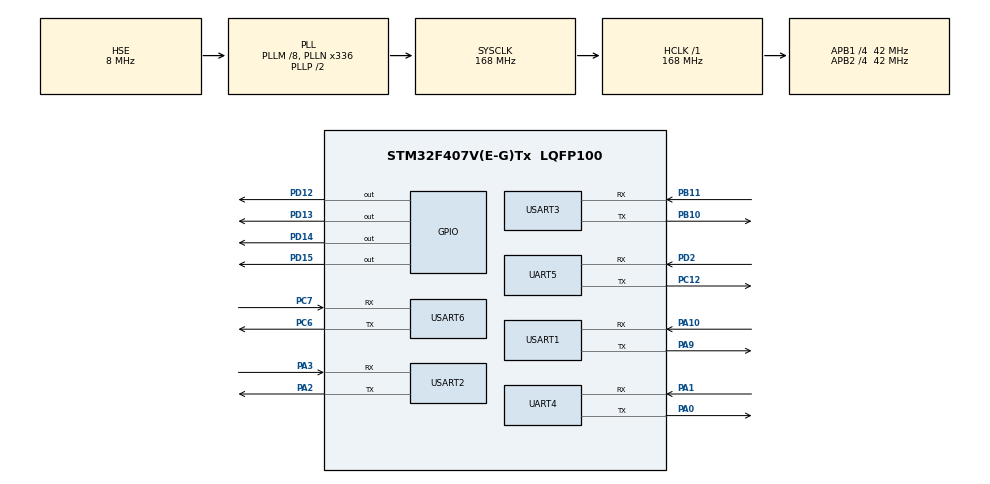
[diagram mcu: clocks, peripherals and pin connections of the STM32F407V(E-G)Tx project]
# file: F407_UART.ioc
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Mcu.Family=STM32F4
NVIC.USART3_IRQn=true\:0\:0\:false\:false\:true\:true\:true
Dma.USART2_RX.3.Mode=DMA_CIRCULAR
Dma.USART6_RX.5.FIFOMode=DMA_FIFOMODE_DISABLE
Dma.UART5_RX.1.MemInc=DMA_MINC_ENABLE
PH0-OSC_IN.Signal=RCC_OSC_IN
RCC.CortexFreq_Value=168000000
Dma.USART3_RX.4.Priority=DMA_PRIORITY_LOW
PB10.Mode=Asynchronous
Dma.USART6_RX.5.Priority=DMA_PRIORITY_LOW
NVIC.DMA1_Stream2_IRQn=true\:0\:0\:false\:false\:true\:false\:true
PC12.Signal=UART5_TX
Dma.USART1_RX.2.Instance=DMA2_Stream2
Dma.UART5_RX.1.Mode=DMA_CIRCULAR
Dma.USART3_RX.4.MemDataAlignment=DMA_MDATAALIGN_BYTE
Dma.USART6_RX.5.PeriphDataAlignment=DMA_PDATAALIGN_BYTE
PB11.Signal=USART3_RX
RCC.SYSCLKSource=RCC_SYSCLKSOURCE_PLLCLK
ProjectManager.StackSize=0x400
NVIC.UART5_IRQn=true\:0\:0\:false\:false\:true\:true\:true
Dma.USART6_RX.5.MemInc=DMA_MINC_ENABLE
PD13.Signal=GPIO_Output
Dma.USART6_RX.5.Instance=DMA2_Stream1
RCC.HCLKFreq_Value=168000000
RCC.APB2TimFreq_Value=84000000
PC7.Signal=USART6_RX
RCC.AHBFreq_Value=168000000
PH0-OSC_IN.Mode=HSE-External-Oscillator
RCC.HSE_VALUE=8000000
Dma.UART4_RX.0.MemDataAlignment=DMA_MDATAALIGN_BYTE
Dma.USART3_RX.4.PeriphInc=DMA_PINC_DISABLE
Dma.UART4_RX.0.PeriphDataAlignment=DMA_PDATAALIGN_BYTE
Dma.USART2_RX.3.Direction=DMA_PERIPH_TO_MEMORY
PH1-OSC_OUT.Mode=HSE-External-Oscillator
Mcu.Package=LQFP100
Dma.USART6_RX.5.PeriphInc=DMA_PINC_DISABLE
USART2.VirtualMode=VM_ASYNC
USART6.VirtualMode=VM_ASYNC
PD12.Signal=GPIO_Output
Dma.USART6_RX.5.Mode=DMA_CIRCULAR
PA10.Signal=USART1_RX
Dma.USART3_RX.4.Instance=DMA1_Stream1
RCC.APB2CLKDivider=RCC_HCLK_DIV4
Dma.USART2_RX.3.MemDataAlignment=DMA_MDATAALIGN_BYTE
NVIC.DMA2_Stream2_IRQn=true\:0\:0\:false\:false\:true\:false\:true
Dma.Request2=USART1_RX
Dma.Request1=UART5_RX
RCC.APB1TimFreq_Value=84000000
Dma.Request4=USART3_RX
Dma.Request3=USART2_RX
Dma.Request5=USART6_RX
NVIC.DMA1_Stream0_IRQn=true\:0\:0\:false\:false\:true\:false\:true
NVIC.USART1_IRQn=true\:0\:0\:false\:false\:true\:true\:true
Dma.Request0=UART4_RX
PD15.Signal=GPIO_Output
Dma.USART3_RX.4.FIFOMode=DMA_FIFOMODE_DISABLE
Dma.USART1_RX.2.MemDataAlignment=DMA_MDATAALIGN_BYTE
PA3.Signal=USART2_RX
NVIC.UART4_IRQn=true\:0\:0\:false\:false\:true\:true\:true
Dma.UART4_RX.0.MemInc=DMA_MINC_ENABLE
RCC.PLLSourceVirtual=RCC_PLLSOURCE_HSE
PA10.Mode=Asynchronous
Dma.USART2_RX.3.Instance=DMA1_Stream5
Dma.UART5_RX.1.MemDataAlignment=DMA_MDATAALIGN_BYTE
Dma.UART4_RX.0.Mode=DMA_CIRCULAR
PC6.Signal=USART6_TX
Dma.USART2_RX.3.PeriphDataAlignment=DMA_PDATAALIGN_BYTE
NVIC.DMA1_Stream1_IRQn=true\:0\:0\:false\:false\:true\:false\:true
NVIC.DMA2_Stream1_IRQn=true\:0\:0\:false\:false\:true\:false\:true
UART5.VirtualMode=Asynchronous
RCC.APB1CLKDivider=RCC_HCLK_DIV4
UART4.VirtualMode=Asynchronous
Dma.USART1_RX.2.PeriphInc=DMA_PINC_DISABLE
Dma.USART3_RX.4.PeriphDataAlignment=DMA_PDATAALIGN_BYTE
NVIC.USART2_IRQn=true\:0\:0\:false\:false\:true\:true\:true
PA0-WKUP.Signal=UART4_TX
NVIC.USART6_IRQn=true\:0\:0\:false\:false\:true\:true\:true
PA0-WKUP.Mode=Asynchronous
PA3.Mode=Asynchronous
Dma.UART5_RX.1.FIFOMode=DMA_FIFOMODE_DISABLE
Dma.USART2_RX.3.FIFOMode=DMA_FIFOMODE_DISABLE
PA9.Mode=Asynchronous
Dma.USART3_RX.4.Mode=DMA_CIRCULAR
Dma.UART4_RX.0.Direction=DMA_PERIPH_TO_MEMORY
PB11.Mode=Asynchronous
ProjectManager.TargetToolchain=STM32CubeIDE
NVIC.DMA1_Stream5_IRQn=true\:0\:0\:false\:false\:true\:false\:true
Dma.USART1_RX.2.Mode=DMA_CIRCULAR
PC6.Mode=Asynchronous
Dma.USART1_RX.2.PeriphDataAlignment=DMA_PDATAALIGN_BYTE
PA9.Signal=USART1_TX
Dma.UART4_RX.0.PeriphInc=DMA_PINC_DISABLE
RCC.LSE_VALUE=32768
PA1.Signal=UART4_RX
PB10.Signal=USART3_TX
PD2.Mode=Asynchronous
Dma.UART5_RX.1.Direction=DMA_PERIPH_TO_MEMORY
Dma.UART5_RX.1.Instance=DMA1_Stream0
PC12.Mode=Asynchronous
board=custom
Dma.USART1_RX.2.FIFOMode=DMA_FIFOMODE_DISABLE
RCC.VCOOutputFreq_Value=336000000
Dma.UART4_RX.0.FIFOMode=DMA_FIFOMODE_DISABLE
Dma.USART1_RX.2.Priority=DMA_PRIORITY_LOW
Dma.UART5_RX.1.PeriphInc=DMA_PINC_DISABLE
Dma.UART4_RX.0.Priority=DMA_PRIORITY_LOW
RCC.APB2Freq_Value=42000000
PA1.Mode=Asynchronous
Dma.USART1_RX.2.Direction=DMA_PERIPH_TO_MEMORY
Dma.USART6_RX.5.MemDataAlignment=DMA_MDATAALIGN_BYTE
Dma.UART5_RX.1.PeriphDataAlignment=DMA_PDATAALIGN_BYTE
PH1-OSC_OUT.Signal=RCC_OSC_OUT
Dma.USART6_RX.5.Direction=DMA_PERIPH_TO_MEMORY
Mcu.Name=STM32F407V(E-G)Tx
Dma.USART1_RX.2.MemInc=DMA_MINC_ENABLE
PA2.Signal=USART2_TX
PD14.Signal=GPIO_Output
RCC.48MHZClocksFreq_Value=84000000
RCC.SYSCLKFreq_VALUE=168000000
USART3.VirtualMode=VM_ASYNC
USART1.VirtualMode=VM_ASYNC
ProjectManager.HeapSize=0x200
Dma.USART2_RX.3.MemInc=DMA_MINC_ENABLE
Dma.USART2_RX.3.PeriphInc=DMA_PINC_DISABLE
Dma.USART3_RX.4.MemInc=DMA_MINC_ENABLE
RCC.HSI_VALUE=16000000
Dma.USART3_RX.4.Direction=DMA_PERIPH_TO_MEMORY
NVIC.PriorityGroup=NVIC_PRIORITYGROUP_4
RCC.PLLM=8
RCC.PLLN=336
Dma.USART2_RX.3.Priority=DMA_PRIORITY_LOW
Dma.UART4_RX.0.Instance=DMA1_Stream2
PA2.Mode=Asynchronous
PC7.Mode=Asynchronous
PD2.Signal=UART5_RX
RCC.APB1Freq_Value=42000000
Dma.UART5_RX.1.Priority=DMA_PRIORITY_LOW

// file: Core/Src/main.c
/* USER CODE BEGIN Header */
/**
  ******************************************************************************
  * @file           : main.c
  * @brief          : Main program body
  ******************************************************************************
  * @attention
  *
  * <h2><center>&copy; Copyright (c) 2021 STMicroelectronics.
  * All rights reserved.</center></h2>
  *
  * This software component is licensed by ST under BSD 3-Clause license,
  * the "License"; You may not use this file except in compliance with the
  * License. You may obtain a copy of the License at:
  *                        opensource.org/licenses/BSD-3-Clause
  *
  ******************************************************************************
  */
/* USER CODE END Header */
#include "main.h"

UART_HandleTypeDef huart4;
UART_HandleTypeDef huart5;
UART_HandleTypeDef huart1;
UART_HandleTypeDef huart2;
UART_HandleTypeDef huart3;
UART_HandleTypeDef huart6;
DMA_HandleTypeDef hdma_uart4_rx;
DMA_HandleTypeDef hdma_uart5_rx;
DMA_HandleTypeDef hdma_usart1_rx;
DMA_HandleTypeDef hdma_usart2_rx;
DMA_HandleTypeDef hdma_usart3_rx;
DMA_HandleTypeDef hdma_usart6_rx;

void SystemClock_Config(void);
static void MX_GPIO_Init(void);
static void MX_DMA_Init(void);
static void MX_UART4_Init(void);
static void MX_UART5_Init(void);
static void MX_USART1_UART_Init(void);
static void MX_USART2_UART_Init(void);
static void MX_USART3_UART_Init(void);
static void MX_USART6_UART_Init(void);
/* USER CODE BEGIN PFP */
int __io_putchar (int ch) {
	uint8_t c = ch;
	HAL_UART_Transmit(&huart4, &c, 1, HAL_MAX_DELAY);
	return ch;
}
/* USER CODE END PFP */

/* USER CODE BEGIN 0 */
uint8_t receive_data = 0;
/* USER CODE END 0 */

int main(void)
{

  /* MCU Configuration--------------------------------------------------------*/

  /* Reset of all peripherals, Initializes the Flash interface and the Systick. */
  HAL_Init();

  /* Configure the system clock */
  SystemClock_Config();

  /* Initialize all configured peripherals */
  MX_GPIO_Init();
  MX_DMA_Init();
  MX_UART4_Init();
  MX_UART5_Init();
  MX_USART1_UART_Init();
  MX_USART2_UART_Init();
  MX_USART3_UART_Init();
  MX_USART6_UART_Init();
  /* USER CODE BEGIN 2 */
  HAL_UART_Receive_DMA(&huart4, &receive_data, 1);
  /* USER CODE END 2 */

  /* Infinite loop */
  while (1)
  {

  }
}

void SystemClock_Config(void)
{
  RCC_OscInitTypeDef RCC_OscInitStruct = {0};
  RCC_ClkInitTypeDef RCC_ClkInitStruct = {0};

  /** Configure the main internal regulator output voltage
  */
  __HAL_RCC_PWR_CLK_ENABLE();
  __HAL_PWR_VOLTAGESCALING_CONFIG(PWR_REGULATOR_VOLTAGE_SCALE1);
  /** Initializes the RCC Oscillators according to the specified parameters
  * in the RCC_OscInitTypeDef structure.
  */
  RCC_OscInitStruct.OscillatorType = RCC_OSCILLATORTYPE_HSE;
  RCC_OscInitStruct.HSEState = RCC_HSE_ON;
  RCC_OscInitStruct.PLL.PLLState = RCC_PLL_ON;
  RCC_OscInitStruct.PLL.PLLSource = RCC_PLLSOURCE_HSE;
  RCC_OscInitStruct.PLL.PLLM = 8;
  RCC_OscInitStruct.PLL.PLLN = 336;
  RCC_OscInitStruct.PLL.PLLP = RCC_PLLP_DIV2;
  RCC_OscInitStruct.PLL.PLLQ = 4;
  if (HAL_RCC_OscConfig(&RCC_OscInitStruct) != HAL_OK)
  {
    Error_Handler();
  }
  /** Initializes the CPU, AHB and APB buses clocks
  */
  RCC_ClkInitStruct.ClockType = RCC_CLOCKTYPE_HCLK|RCC_CLOCKTYPE_SYSCLK
                              |RCC_CLOCKTYPE_PCLK1|RCC_CLOCKTYPE_PCLK2;
  RCC_ClkInitStruct.SYSCLKSource = RCC_SYSCLKSOURCE_PLLCLK;
  RCC_ClkInitStruct.AHBCLKDivider = RCC_SYSCLK_DIV1;
  RCC_ClkInitStruct.APB1CLKDivider = RCC_HCLK_DIV4;
  RCC_ClkInitStruct.APB2CLKDivider = RCC_HCLK_DIV4;

  if (HAL_RCC_ClockConfig(&RCC_ClkInitStruct, FLASH_LATENCY_5) != HAL_OK)
  {
    Error_Handler();
  }
}

static void MX_UART4_Init(void)
{

  huart4.Instance = UART4;
  huart4.Init.BaudRate = 115200;
  huart4.Init.WordLength = UART_WORDLENGTH_8B;
  huart4.Init.StopBits = UART_STOPBITS_1;
  huart4.Init.Parity = UART_PARITY_NONE;
  huart4.Init.Mode = UART_MODE_TX_RX;
  huart4.Init.HwFlowCtl = UART_HWCONTROL_NONE;
  huart4.Init.OverSampling = UART_OVERSAMPLING_16;
  if (HAL_UART_Init(&huart4) != HAL_OK)
  {
    Error_Handler();
  }

}

static void MX_UART5_Init(void)
{

  huart5.Instance = UART5;
  huart5.Init.BaudRate = 115200;
  huart5.Init.WordLength = UART_WORDLENGTH_8B;
  huart5.Init.StopBits = UART_STOPBITS_1;
  huart5.Init.Parity = UART_PARITY_NONE;
  huart5.Init.Mode = UART_MODE_TX_RX;
  huart5.Init.HwFlowCtl = UART_HWCONTROL_NONE;
  huart5.Init.OverSampling = UART_OVERSAMPLING_16;
  if (HAL_UART_Init(&huart5) != HAL_OK)
  {
    Error_Handler();
  }

}

static void MX_USART1_UART_Init(void)
{

  huart1.Instance = USART1;
  huart1.Init.BaudRate = 115200;
  huart1.Init.WordLength = UART_WORDLENGTH_8B;
  huart1.Init.StopBits = UART_STOPBITS_1;
  huart1.Init.Parity = UART_PARITY_NONE;
  huart1.Init.Mode = UART_MODE_TX_RX;
  huart1.Init.HwFlowCtl = UART_HWCONTROL_NONE;
  huart1.Init.OverSampling = UART_OVERSAMPLING_16;
  if (HAL_UART_Init(&huart1) != HAL_OK)
  {
    Error_Handler();
  }

}

static void MX_USART2_UART_Init(void)
{

  huart2.Instance = USART2;
  huart2.Init.BaudRate = 115200;
  huart2.Init.WordLength = UART_WORDLENGTH_8B;
  huart2.Init.StopBits = UART_STOPBITS_1;
  huart2.Init.Parity = UART_PARITY_NONE;
  huart2.Init.Mode = UART_MODE_TX_RX;
  huart2.Init.HwFlowCtl = UART_HWCONTROL_NONE;
  huart2.Init.OverSampling = UART_OVERSAMPLING_16;
  if (HAL_UART_Init(&huart2) != HAL_OK)
  {
    Error_Handler();
  }

}

static void MX_USART3_UART_Init(void)
{

  huart3.Instance = USART3;
  huart3.Init.BaudRate = 115200;
  huart3.Init.WordLength = UART_WORDLENGTH_8B;
  huart3.Init.StopBits = UART_STOPBITS_1;
  huart3.Init.Parity = UART_PARITY_NONE;
  huart3.Init.Mode = UART_MODE_TX_RX;
  huart3.Init.HwFlowCtl = UART_HWCONTROL_NONE;
  huart3.Init.OverSampling = UART_OVERSAMPLING_16;
  if (HAL_UART_Init(&huart3) != HAL_OK)
  {
    Error_Handler();
  }

}

static void MX_USART6_UART_Init(void)
{

  huart6.Instance = USART6;
  huart6.Init.BaudRate = 115200;
  huart6.Init.WordLength = UART_WORDLENGTH_8B;
  huart6.Init.StopBits = UART_STOPBITS_1;
  huart6.Init.Parity = UART_PARITY_NONE;
  huart6.Init.Mode = UART_MODE_TX_RX;
  huart6.Init.HwFlowCtl = UART_HWCONTROL_NONE;
  huart6.Init.OverSampling = UART_OVERSAMPLING_16;
  if (HAL_UART_Init(&huart6) != HAL_OK)
  {
    Error_Handler();
  }

}

static void MX_DMA_Init(void)
{

  /* DMA controller clock enable */
  __HAL_RCC_DMA1_CLK_ENABLE();
  __HAL_RCC_DMA2_CLK_ENABLE();

  /* DMA interrupt init */
  /* DMA1_Stream0_IRQn interrupt configuration */
  HAL_NVIC_SetPriority(DMA1_Stream0_IRQn, 0, 0);
  HAL_NVIC_EnableIRQ(DMA1_Stream0_IRQn);
  /* DMA1_Stream1_IRQn interrupt configuration */
  HAL_NVIC_SetPriority(DMA1_Stream1_IRQn, 0, 0);
  HAL_NVIC_EnableIRQ(DMA1_Stream1_IRQn);
  /* DMA1_Stream2_IRQn interrupt configuration */
  HAL_NVIC_SetPriority(DMA1_Stream2_IRQn, 0, 0);
  HAL_NVIC_EnableIRQ(DMA1_Stream2_IRQn);
  /* DMA1_Stream5_IRQn interrupt configuration */
  HAL_NVIC_SetPriority(DMA1_Stream5_IRQn, 0, 0);
  HAL_NVIC_EnableIRQ(DMA1_Stream5_IRQn);
  /* DMA2_Stream1_IRQn interrupt configuration */
  HAL_NVIC_SetPriority(DMA2_Stream1_IRQn, 0, 0);
  HAL_NVIC_EnableIRQ(DMA2_Stream1_IRQn);
  /* DMA2_Stream2_IRQn interrupt configuration */
  HAL_NVIC_SetPriority(DMA2_Stream2_IRQn, 0, 0);
  HAL_NVIC_EnableIRQ(DMA2_Stream2_IRQn);

}

static void MX_GPIO_Init(void)
{
  GPIO_InitTypeDef GPIO_InitStruct = {0};

  /* GPIO Ports Clock Enable */
  __HAL_RCC_GPIOH_CLK_ENABLE();
  __HAL_RCC_GPIOA_CLK_ENABLE();
  __HAL_RCC_GPIOB_CLK_ENABLE();
  __HAL_RCC_GPIOD_CLK_ENABLE();
  __HAL_RCC_GPIOC_CLK_ENABLE();

  /*Configure GPIO pin Output Level */
  HAL_GPIO_WritePin(GPIOD, GPIO_PIN_12|GPIO_PIN_13|GPIO_PIN_14|GPIO_PIN_15, GPIO_PIN_RESET);

  /*Configure GPIO pins : PD12 PD13 PD14 PD15 */
  GPIO_InitStruct.Pin = GPIO_PIN_12|GPIO_PIN_13|GPIO_PIN_14|GPIO_PIN_15;
  GPIO_InitStruct.Mode = GPIO_MODE_OUTPUT_PP;
  GPIO_InitStruct.Pull = GPIO_NOPULL;
  GPIO_InitStruct.Speed = GPIO_SPEED_FREQ_LOW;
  HAL_GPIO_Init(GPIOD, &GPIO_InitStruct);

}

void Error_Handler(void)
{
  /* USER CODE BEGIN Error_Handler_Debug */
  /* User can add his own implementation to report the HAL error return state */
//  __disable_irq();
//  while (1)
//  {
//  }
  /* USER CODE END Error_Handler_Debug */
}

/************************ (C) COPYRIGHT STMicroelectronics *****END OF FILE****/
